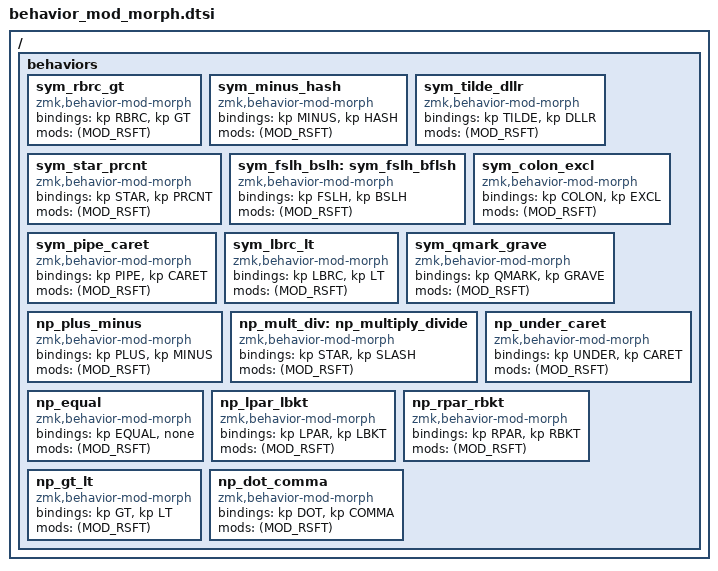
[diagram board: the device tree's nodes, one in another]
/ {
    behaviors {

	/*
	 * Symbol
	 *
	 * These mod morphs are intented to be used on the symbol layer.
	 * These morphs attempt to arrange symbols commonly used while
	 * programming in a logical and easy to type arrangement.
	 */

	sym_rbrc_gt: sym_rbrc_gt {
	    compatible = "zmk,behavior-mod-morph";
            #binding-cells = <0>;
            bindings = <&kp RBRC>, <&kp GT>;
            mods = <(MOD_RSFT)>;
	};

	sym_minus_hash: sym_minus_hash {
	    compatible = "zmk,behavior-mod-morph";
            #binding-cells = <0>;
            bindings = <&kp MINUS>, <&kp HASH>;
            mods = <(MOD_RSFT)>;
	};

	sym_tilde_dllr: sym_tilde_dllr {
	    compatible = "zmk,behavior-mod-morph";
            #binding-cells = <0>;
            bindings = <&kp TILDE>, <&kp DLLR>;
            mods = <(MOD_RSFT)>;
	};

	sym_star_prcnt: sym_star_prcnt {
	    compatible = "zmk,behavior-mod-morph";
            #binding-cells = <0>;
            bindings = <&kp STAR>, <&kp PRCNT>;
            mods = <(MOD_RSFT)>;
	};

	sym_fslh_bslh: sym_fslh_bflsh {
	    compatible = "zmk,behavior-mod-morph";
            #binding-cells = <0>;
            bindings = <&kp FSLH>, <&kp BSLH>;
            mods = <(MOD_RSFT)>;
	};

	sym_colon_excl: sym_colon_excl {
	    compatible = "zmk,behavior-mod-morph";
            #binding-cells = <0>;
            bindings = <&kp COLON>, <&kp EXCL>;
            mods = <(MOD_RSFT)>;
	};

	sym_pipe_caret: sym_pipe_caret {
	    compatible = "zmk,behavior-mod-morph";
            #binding-cells = <0>;
            bindings = <&kp PIPE>, <&kp CARET>;
            mods = <(MOD_RSFT)>;
	};

	sym_lbrc_lt: sym_lbrc_lt {
	    compatible = "zmk,behavior-mod-morph";
            #binding-cells = <0>;
            bindings = <&kp LBRC>, <&kp LT>;
            mods = <(MOD_RSFT)>;
	};


	sym_qmark_grave: sym_qmark_grave {
	    compatible = "zmk,behavior-mod-morph";
            #binding-cells = <0>;
            bindings = <&kp QMARK>, <&kp GRAVE>;
            mods = <(MOD_RSFT)>;
	};


	/*
	 * Numpad
	 *
	 * These mod morphs are intented to be used on the numpad layer.
	 * They combine symbols that are commonly used with numbers in a
	 * logical arrangement.
	*/
	
	np_plus_minus: np_plus_minus {
	    compatible = "zmk,behavior-mod-morph";
            #binding-cells = <0>;
            bindings = <&kp PLUS>, <&kp MINUS>;
            mods = <(MOD_RSFT)>;
	};

	np_mult_div: np_multiply_divide {
	    compatible = "zmk,behavior-mod-morph";
            #binding-cells = <0>;
            bindings = <&kp STAR>, <&kp SLASH>;
            mods = <(MOD_RSFT)>;
	};

	np_under_caret: np_under_caret {
	    compatible = "zmk,behavior-mod-morph";
            #binding-cells = <0>;
            bindings = <&kp UNDER>, <&kp CARET>;
            mods = <(MOD_RSFT)>;
	};

	np_equal: np_equal {
	    compatible = "zmk,behavior-mod-morph";
            #binding-cells = <0>;
            bindings = <&kp EQUAL>, <&none>;
            mods = <(MOD_RSFT)>;
	};

	np_lpar_lbkt: np_lpar_lbkt {
	    compatible = "zmk,behavior-mod-morph";
            #binding-cells = <0>;
            bindings = <&kp LPAR>, <&kp LBKT>;
            mods = <(MOD_RSFT)>;
	};

	np_rpar_rbkt: np_rpar_rbkt {
	    compatible = "zmk,behavior-mod-morph";
            #binding-cells = <0>;
            bindings = <&kp RPAR>, <&kp RBKT>;
            mods = <(MOD_RSFT)>;
	};

	np_gt_lt: np_gt_lt {
	    compatible = "zmk,behavior-mod-morph";
            #binding-cells = <0>;
            bindings = <&kp GT>, <&kp LT>;
            mods = <(MOD_RSFT)>;
	};

	np_dot_comma: np_dot_comma {
	    compatible = "zmk,behavior-mod-morph";
            #binding-cells = <0>;
            bindings = <&kp DOT>, <&kp COMMA>;
            mods = <(MOD_RSFT)>;
	};
    };
};
